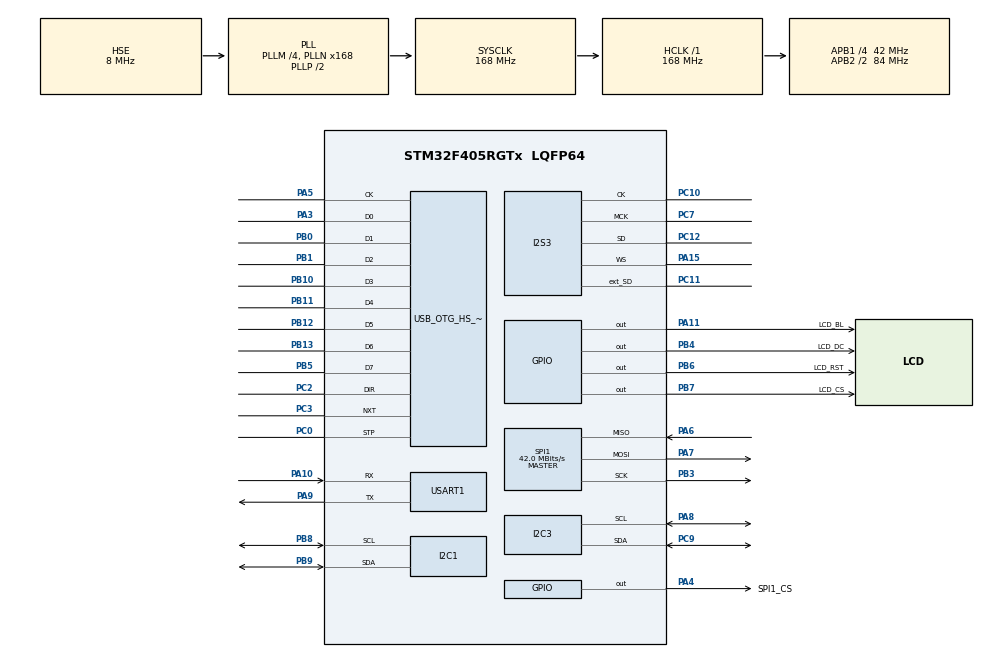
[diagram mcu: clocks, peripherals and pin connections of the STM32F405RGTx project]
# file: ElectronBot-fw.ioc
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Dma.I2C1_RX.5.Direction=DMA_PERIPH_TO_MEMORY
Dma.I2C1_RX.5.FIFOMode=DMA_FIFOMODE_DISABLE
Dma.I2C1_RX.5.Instance=DMA1_Stream5
Dma.I2C1_RX.5.MemDataAlignment=DMA_MDATAALIGN_BYTE
Dma.I2C1_RX.5.MemInc=DMA_MINC_ENABLE
Dma.I2C1_RX.5.Mode=DMA_NORMAL
Dma.I2C1_RX.5.PeriphDataAlignment=DMA_PDATAALIGN_BYTE
Dma.I2C1_RX.5.PeriphInc=DMA_PINC_DISABLE
Dma.I2C1_RX.5.Priority=DMA_PRIORITY_LOW
Dma.I2C1_TX.4.Direction=DMA_MEMORY_TO_PERIPH
Dma.I2C1_TX.4.FIFOMode=DMA_FIFOMODE_DISABLE
Dma.I2C1_TX.4.Instance=DMA1_Stream6
Dma.I2C1_TX.4.MemDataAlignment=DMA_MDATAALIGN_BYTE
Dma.I2C1_TX.4.MemInc=DMA_MINC_ENABLE
Dma.I2C1_TX.4.Mode=DMA_NORMAL
Dma.I2C1_TX.4.PeriphDataAlignment=DMA_PDATAALIGN_BYTE
Dma.I2C1_TX.4.PeriphInc=DMA_PINC_DISABLE
Dma.I2C1_TX.4.Priority=DMA_PRIORITY_LOW
Dma.I2C3_RX.7.Direction=DMA_PERIPH_TO_MEMORY
Dma.I2C3_RX.7.FIFOMode=DMA_FIFOMODE_DISABLE
Dma.I2C3_RX.7.Instance=DMA1_Stream2
Dma.I2C3_RX.7.MemDataAlignment=DMA_MDATAALIGN_BYTE
Dma.I2C3_RX.7.MemInc=DMA_MINC_ENABLE
Dma.I2C3_RX.7.Mode=DMA_NORMAL
Dma.I2C3_RX.7.PeriphDataAlignment=DMA_PDATAALIGN_BYTE
Dma.I2C3_RX.7.PeriphInc=DMA_PINC_DISABLE
Dma.I2C3_RX.7.Priority=DMA_PRIORITY_LOW
Dma.I2C3_TX.6.Direction=DMA_MEMORY_TO_PERIPH
Dma.I2C3_TX.6.FIFOMode=DMA_FIFOMODE_DISABLE
Dma.I2C3_TX.6.Instance=DMA1_Stream4
Dma.I2C3_TX.6.MemDataAlignment=DMA_MDATAALIGN_BYTE
Dma.I2C3_TX.6.MemInc=DMA_MINC_ENABLE
Dma.I2C3_TX.6.Mode=DMA_NORMAL
Dma.I2C3_TX.6.PeriphDataAlignment=DMA_PDATAALIGN_BYTE
Dma.I2C3_TX.6.PeriphInc=DMA_PINC_DISABLE
Dma.I2C3_TX.6.Priority=DMA_PRIORITY_LOW
Dma.I2S3_EXT_RX.3.Direction=DMA_PERIPH_TO_MEMORY
Dma.I2S3_EXT_RX.3.FIFOMode=DMA_FIFOMODE_DISABLE
Dma.I2S3_EXT_RX.3.Instance=DMA1_Stream0
Dma.I2S3_EXT_RX.3.MemDataAlignment=DMA_MDATAALIGN_HALFWORD
Dma.I2S3_EXT_RX.3.MemInc=DMA_MINC_ENABLE
Dma.I2S3_EXT_RX.3.Mode=DMA_NORMAL
Dma.I2S3_EXT_RX.3.PeriphDataAlignment=DMA_PDATAALIGN_HALFWORD
Dma.I2S3_EXT_RX.3.PeriphInc=DMA_PINC_DISABLE
Dma.I2S3_EXT_RX.3.Priority=DMA_PRIORITY_LOW
Dma.Request0=USART1_RX
Dma.Request1=USART1_TX
Dma.Request2=SPI3_TX
Dma.Request3=I2S3_EXT_RX
Dma.Request4=I2C1_TX
Dma.Request5=I2C1_RX
Dma.Request6=I2C3_TX
Dma.Request7=I2C3_RX
Dma.Request8=SPI1_RX
Dma.Request9=SPI1_TX
Dma.SPI1_RX.8.Direction=DMA_PERIPH_TO_MEMORY
Dma.SPI1_RX.8.FIFOMode=DMA_FIFOMODE_DISABLE
Dma.SPI1_RX.8.Instance=DMA2_Stream0
Dma.SPI1_RX.8.MemDataAlignment=DMA_MDATAALIGN_BYTE
Dma.SPI1_RX.8.MemInc=DMA_MINC_ENABLE
Dma.SPI1_RX.8.Mode=DMA_NORMAL
Dma.SPI1_RX.8.PeriphDataAlignment=DMA_PDATAALIGN_BYTE
Dma.SPI1_RX.8.PeriphInc=DMA_PINC_DISABLE
Dma.SPI1_RX.8.Priority=DMA_PRIORITY_LOW
Dma.SPI1_TX.9.Direction=DMA_MEMORY_TO_PERIPH
Dma.SPI1_TX.9.FIFOMode=DMA_FIFOMODE_DISABLE
Dma.SPI1_TX.9.Instance=DMA2_Stream3
Dma.SPI1_TX.9.MemDataAlignment=DMA_MDATAALIGN_BYTE
Dma.SPI1_TX.9.MemInc=DMA_MINC_ENABLE
Dma.SPI1_TX.9.Mode=DMA_NORMAL
Dma.SPI1_TX.9.PeriphDataAlignment=DMA_PDATAALIGN_BYTE
Dma.SPI1_TX.9.PeriphInc=DMA_PINC_DISABLE
Dma.SPI1_TX.9.Priority=DMA_PRIORITY_LOW
Dma.SPI3_TX.2.Direction=DMA_MEMORY_TO_PERIPH
Dma.SPI3_TX.2.FIFOMode=DMA_FIFOMODE_DISABLE
Dma.SPI3_TX.2.Instance=DMA1_Stream7
Dma.SPI3_TX.2.MemDataAlignment=DMA_MDATAALIGN_HALFWORD
Dma.SPI3_TX.2.MemInc=DMA_MINC_ENABLE
Dma.SPI3_TX.2.Mode=DMA_NORMAL
Dma.SPI3_TX.2.PeriphDataAlignment=DMA_PDATAALIGN_HALFWORD
Dma.SPI3_TX.2.PeriphInc=DMA_PINC_DISABLE
Dma.SPI3_TX.2.Priority=DMA_PRIORITY_LOW
Dma.USART1_RX.0.Direction=DMA_PERIPH_TO_MEMORY
Dma.USART1_RX.0.FIFOMode=DMA_FIFOMODE_DISABLE
Dma.USART1_RX.0.Instance=DMA2_Stream2
Dma.USART1_RX.0.MemDataAlignment=DMA_MDATAALIGN_BYTE
Dma.USART1_RX.0.MemInc=DMA_MINC_ENABLE
Dma.USART1_RX.0.Mode=DMA_CIRCULAR
Dma.USART1_RX.0.PeriphDataAlignment=DMA_PDATAALIGN_BYTE
Dma.USART1_RX.0.PeriphInc=DMA_PINC_DISABLE
Dma.USART1_RX.0.Priority=DMA_PRIORITY_LOW
Dma.USART1_TX.1.Direction=DMA_MEMORY_TO_PERIPH
Dma.USART1_TX.1.FIFOMode=DMA_FIFOMODE_DISABLE
Dma.USART1_TX.1.Instance=DMA2_Stream7
Dma.USART1_TX.1.MemDataAlignment=DMA_MDATAALIGN_BYTE
Dma.USART1_TX.1.MemInc=DMA_MINC_ENABLE
Dma.USART1_TX.1.Mode=DMA_NORMAL
Dma.USART1_TX.1.PeriphDataAlignment=DMA_PDATAALIGN_BYTE
Dma.USART1_TX.1.PeriphInc=DMA_PINC_DISABLE
Dma.USART1_TX.1.Priority=DMA_PRIORITY_LOW
FREERTOS.Tasks01=defaultTask,24,128,StartDefaultTask,Default,NULL,Dynamic,NULL,NULL
FREERTOS.configENABLE_FPU=1
FREERTOS.configTOTAL_HEAP_SIZE=10000
I2C1.I2C_Mode=I2C_Standard
I2S3.AudioFreq=I2S_AUDIOFREQ_44K
I2S3.DataFormat=I2S_DATAFORMAT_16B_EXTENDED
I2S3.ErrorAudioFreq=0.26 %
I2S3.FullDuplexMode=I2S_FULLDUPLEXMODE_ENABLE
I2S3.Instance=SPI$Index
I2S3.RealAudioFreq=44.117 KHz
I2S3.VirtualMode=I2S_MODE_MASTER
Mcu.Family=STM32F4
Mcu.Name=STM32F405RGTx
Mcu.Package=LQFP64
NVIC.DMA1_Stream0_IRQn=true\:5\:0\:false\:false\:true\:true\:false\:true
NVIC.DMA1_Stream2_IRQn=true\:5\:0\:false\:false\:true\:true\:false\:true
NVIC.DMA1_Stream4_IRQn=true\:5\:0\:false\:false\:true\:true\:false\:true
NVIC.DMA1_Stream5_IRQn=true\:5\:0\:false\:false\:true\:true\:false\:true
NVIC.DMA1_Stream6_IRQn=true\:5\:0\:false\:false\:true\:true\:false\:true
NVIC.DMA1_Stream7_IRQn=true\:5\:0\:false\:false\:true\:true\:false\:true
NVIC.DMA2_Stream0_IRQn=true\:5\:0\:false\:false\:true\:true\:false\:true
NVIC.DMA2_Stream2_IRQn=true\:5\:0\:false\:false\:true\:true\:false\:true
NVIC.DMA2_Stream3_IRQn=true\:5\:0\:false\:false\:true\:true\:false\:true
NVIC.DMA2_Stream7_IRQn=true\:5\:0\:false\:false\:true\:true\:false\:true
NVIC.I2C1_ER_IRQn=true\:5\:0\:false\:false\:true\:true\:true\:true
NVIC.I2C1_EV_IRQn=true\:5\:0\:false\:false\:true\:true\:true\:true
NVIC.I2C3_ER_IRQn=true\:5\:0\:false\:false\:true\:true\:true\:true
NVIC.I2C3_EV_IRQn=true\:5\:0\:false\:false\:true\:true\:true\:true
NVIC.OTG_HS_EP1_IN_IRQn=true\:5\:0\:false\:false\:true\:true\:true\:true
NVIC.OTG_HS_EP1_OUT_IRQn=true\:5\:0\:false\:false\:true\:true\:true\:true
NVIC.OTG_HS_IRQn=true\:5\:0\:false\:false\:true\:true\:false\:true
NVIC.PriorityGroup=NVIC_PRIORITYGROUP_4
NVIC.SPI1_IRQn=true\:5\:0\:false\:false\:true\:true\:true\:true
NVIC.SPI3_IRQn=true\:5\:0\:false\:false\:true\:true\:true\:true
NVIC.TIM4_IRQn=true\:5\:0\:false\:false\:true\:true\:true\:true
NVIC.TIM8_TRG_COM_TIM14_IRQn=true\:0\:0\:false\:false\:true\:false\:false\:true
NVIC.TimeBase=TIM8_TRG_COM_TIM14_IRQn
NVIC.TimeBaseIP=TIM14
NVIC.USART1_IRQn=true\:5\:0\:false\:false\:true\:true\:true\:true
PA10.Mode=Asynchronous
PA10.Signal=USART1_RX
PA11.GPIO_Label=LCD_BL
PA11.Signal=GPIO_Output
PA13.Mode=Serial_Wire
PA13.Signal=SYS_JTMS-SWDIO
PA14.Mode=Serial_Wire
PA14.Signal=SYS_JTCK-SWCLK
PA15.Mode=Full_Duplex_Master
PA15.Signal=I2S3_WS
PA3.Mode=Device_HS
PA3.Signal=USB_OTG_HS_ULPI_D0
PA4.GPIO_Label=SPI1_CS
PA4.GPIO_Speed=GPIO_SPEED_FREQ_VERY_HIGH
PA4.Signal=GPIO_Output
PA5.Mode=Device_HS
PA5.Signal=USB_OTG_HS_ULPI_CK
PA6.Mode=Full_Duplex_Master
PA6.Signal=SPI1_MISO
PA7.Mode=Full_Duplex_Master
PA7.Signal=SPI1_MOSI
PA8.Mode=I2C
PA8.Signal=I2C3_SCL
PA9.Mode=Asynchronous
PA9.Signal=USART1_TX
PB0.Mode=Device_HS
PB0.Signal=USB_OTG_HS_ULPI_D1
PB1.Mode=Device_HS
PB1.Signal=USB_OTG_HS_ULPI_D2
PB10.Mode=Device_HS
PB10.Signal=USB_OTG_HS_ULPI_D3
PB11.Mode=Device_HS
PB11.Signal=USB_OTG_HS_ULPI_D4
PB12.Mode=Device_HS
PB12.Signal=USB_OTG_HS_ULPI_D5
PB13.Mode=Device_HS
PB13.Signal=USB_OTG_HS_ULPI_D6
PB3.Mode=Full_Duplex_Master
PB3.Signal=SPI1_SCK
PB4.GPIO_Label=LCD_DC
PB4.GPIO_Speed=GPIO_SPEED_FREQ_VERY_HIGH
PB4.Signal=GPIO_Output
PB5.Mode=Device_HS
PB5.Signal=USB_OTG_HS_ULPI_D7
PB6.GPIO_Label=LCD_RST
PB6.GPIO_Speed=GPIO_SPEED_FREQ_VERY_HIGH
PB6.Signal=GPIO_Output
PB7.GPIO_Label=LCD_CS
PB7.GPIO_Speed=GPIO_SPEED_FREQ_VERY_HIGH
PB7.Signal=GPIO_Output
PB8.Mode=I2C
PB8.Signal=I2C1_SCL
PB9.Mode=I2C
PB9.Signal=I2C1_SDA
PC0.Mode=Device_HS
PC0.Signal=USB_OTG_HS_ULPI_STP
PC10.Mode=Full_Duplex_Master
PC10.Signal=I2S3_CK
PC11.Mode=Full_Duplex_Master
PC11.Signal=I2S3_ext_SD
PC12.Mode=Full_Duplex_Master
PC12.Signal=I2S3_SD
PC2.Mode=Device_HS
PC2.Signal=USB_OTG_HS_ULPI_DIR
PC3.Mode=Device_HS
PC3.Signal=USB_OTG_HS_ULPI_NXT
PC7.Mode=Master_Clock_Activated
PC7.Signal=I2S3_MCK
PC9.Mode=I2C
PC9.Signal=I2C3_SDA
PH0-OSC_IN.Mode=HSE-External-Oscillator
PH0-OSC_IN.Signal=RCC_OSC_IN
PH1-OSC_OUT.Mode=HSE-External-Oscillator
PH1-OSC_OUT.Signal=RCC_OSC_OUT
ProjectManager.HeapSize=0x800
ProjectManager.StackSize=0x800
ProjectManager.TargetToolchain=SW4STM32
RCC.48MHZClocksFreq_Value=48000000
RCC.AHBFreq_Value=168000000
RCC.APB1CLKDivider=RCC_HCLK_DIV4
RCC.APB1Freq_Value=42000000
RCC.APB1TimFreq_Value=84000000
RCC.APB2CLKDivider=RCC_HCLK_DIV2
RCC.APB2Freq_Value=84000000
RCC.APB2TimFreq_Value=168000000
RCC.CortexFreq_Value=168000000
RCC.HCLKFreq_Value=168000000
RCC.HSE_VALUE=8000000
RCC.HSI_VALUE=16000000
RCC.LSE_VALUE=32768
RCC.PLLM=4
RCC.PLLN=168
RCC.PLLQ=7
RCC.PLLSourceVirtual=RCC_PLLSOURCE_HSE
RCC.SYSCLKFreq_VALUE=168000000
RCC.SYSCLKSource=RCC_SYSCLKSOURCE_PLLCLK
RCC.VCOOutputFreq_Value=336000000
SPI1.CalculateBaudRate=42.0 MBits/s
SPI1.Direction=SPI_DIRECTION_2LINES
SPI1.Mode=SPI_MODE_MASTER
SPI1.VirtualType=VM_MASTER
TIM4.Period=100
TIM4.Prescaler=186 - 1
TIM4.TIM_MasterOutputTrigger=TIM_TRGO_UPDATE
TIM5.Prescaler=168 - 1
USART1.VirtualMode=VM_ASYNC
USB_DEVICE.APP_RX_DATA_SIZE-CDC_HS=4
USB_DEVICE.APP_TX_DATA_SIZE-CDC_HS=4
USB_DEVICE.CLASS_NAME_HS=CDC
USB_DEVICE.PID_CDC_HS=32803
USB_DEVICE.VID-CDC_HS=4097
USB_DEVICE.VirtualMode-CDC_HS=Cdc
USB_DEVICE.VirtualModeHS=Cdc_HS
USB_OTG_HS.VirtualMode-Device_HS=Device_HS
USB_OTG_HS.dma_enable-Device_HS=ENABLE
VP_FREERTOS_VS_CMSIS_V2.Mode=CMSIS_V2
VP_SYS_VS_tim14.Mode=TIM14
VP_TIM4_VS_ClockSourceINT.Mode=Internal
VP_TIM5_VS_ClockSourceINT.Mode=Internal
VP_USB_DEVICE_VS_USB_DEVICE_CDC_HS.Mode=CDC_HS
board=custom

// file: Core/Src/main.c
/* USER CODE BEGIN Header */
/**
  ******************************************************************************
  * @file           : main.c
  * @brief          : Main program body
  ******************************************************************************
  * @attention
  *
  * <h2><center>&copy; Copyright (c) 2021 STMicroelectronics.
  * All rights reserved.</center></h2>
  *
  * This software component is licensed by ST under BSD 3-Clause license,
  * the "License"; You may not use this file except in compliance with the
  * License. You may obtain a copy of the License at:
  *                        opensource.org/licenses/BSD-3-Clause
  *
  ******************************************************************************
  */
/* USER CODE END Header */
#include "main.h"
#include "cmsis_os.h"
#include "dma.h"
#include "i2c.h"
#include "i2s.h"
#include "spi.h"
#include "tim.h"
#include "usart.h"
#include "usb_device.h"
#include "gpio.h"

/* USER CODE BEGIN PV */

// uint8_t completed = 1;

/* USER CODE END PV */

void SystemClock_Config(void);
void MX_FREERTOS_Init(void);

int main(void)
{

  /* MCU Configuration--------------------------------------------------------*/

  /* Reset of all peripherals, Initializes the Flash interface and the Systick. */
  HAL_Init();

  /* USER CODE BEGIN Init */
    HAL_RCC_DeInit();
  /* USER CODE END Init */

  /* Configure the system clock */
  SystemClock_Config();

  /* Initialize all configured peripherals */
  MX_GPIO_Init();
  MX_DMA_Init();
  MX_USART1_UART_Init();
  MX_I2C1_Init();
  MX_I2C3_Init();
  MX_I2S3_Init();
  MX_TIM4_Init();
  MX_TIM5_Init();
  MX_SPI1_Init();

  /* Init scheduler */
  osKernelInitialize();  /* Call init function for freertos objects (in freertos.c) */
  MX_FREERTOS_Init();
  /* Start scheduler */
  osKernelStart();

  /* We should never get here as control is now taken by the scheduler */
  /* Infinite loop */
    while (1)
    {

    }
}

void SystemClock_Config(void)
{
  RCC_OscInitTypeDef RCC_OscInitStruct = {0};
  RCC_ClkInitTypeDef RCC_ClkInitStruct = {0};
  RCC_PeriphCLKInitTypeDef PeriphClkInitStruct = {0};

  /** Configure the main internal regulator output voltage
  */
  __HAL_RCC_PWR_CLK_ENABLE();
  __HAL_PWR_VOLTAGESCALING_CONFIG(PWR_REGULATOR_VOLTAGE_SCALE1);
  /** Initializes the RCC Oscillators according to the specified parameters
  * in the RCC_OscInitTypeDef structure.
  */
  RCC_OscInitStruct.OscillatorType = RCC_OSCILLATORTYPE_HSE;
  RCC_OscInitStruct.HSEState = RCC_HSE_ON;
  RCC_OscInitStruct.PLL.PLLState = RCC_PLL_ON;
  RCC_OscInitStruct.PLL.PLLSource = RCC_PLLSOURCE_HSE;
  RCC_OscInitStruct.PLL.PLLM = 4;
  RCC_OscInitStruct.PLL.PLLN = 168;
  RCC_OscInitStruct.PLL.PLLP = RCC_PLLP_DIV2;
  RCC_OscInitStruct.PLL.PLLQ = 7;
  if (HAL_RCC_OscConfig(&RCC_OscInitStruct) != HAL_OK)
  {
    Error_Handler();
  }
  /** Initializes the CPU, AHB and APB buses clocks
  */
  RCC_ClkInitStruct.ClockType = RCC_CLOCKTYPE_HCLK|RCC_CLOCKTYPE_SYSCLK
                              |RCC_CLOCKTYPE_PCLK1|RCC_CLOCKTYPE_PCLK2;
  RCC_ClkInitStruct.SYSCLKSource = RCC_SYSCLKSOURCE_PLLCLK;
  RCC_ClkInitStruct.AHBCLKDivider = RCC_SYSCLK_DIV1;
  RCC_ClkInitStruct.APB1CLKDivider = RCC_HCLK_DIV4;
  RCC_ClkInitStruct.APB2CLKDivider = RCC_HCLK_DIV2;

  if (HAL_RCC_ClockConfig(&RCC_ClkInitStruct, FLASH_LATENCY_5) != HAL_OK)
  {
    Error_Handler();
  }
  PeriphClkInitStruct.PeriphClockSelection = RCC_PERIPHCLK_I2S;
  PeriphClkInitStruct.PLLI2S.PLLI2SN = 192;
  PeriphClkInitStruct.PLLI2S.PLLI2SR = 2;
  if (HAL_RCCEx_PeriphCLKConfig(&PeriphClkInitStruct) != HAL_OK)
  {
    Error_Handler();
  }
}

 /**
  * @brief  Period elapsed callback in non blocking mode
  * @note   This function is called  when TIM14 interrupt took place, inside
  * HAL_TIM_IRQHandler(). It makes a direct call to HAL_IncTick() to increment
  * a global variable "uwTick" used as application time base.
  * @param  htim : TIM handle
  * @retval None
  */
void HAL_TIM_PeriodElapsedCallback(TIM_HandleTypeDef *htim)
{
  if (htim->Instance == TIM14) {
    HAL_IncTick();
  }
}

void Error_Handler(void)
{
    __disable_irq();
    while (1)
    {
    }
}

/************************ (C) COPYRIGHT STMicroelectronics *****END OF FILE****/

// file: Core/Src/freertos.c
/* USER CODE BEGIN Header */
/**
  ******************************************************************************
  * File Name          : freertos.c
  * Description        : Code for freertos applications
  ******************************************************************************
  * @attention
  *
  * <h2><center>&copy; Copyright (c) 2022 STMicroelectronics.
  * All rights reserved.</center></h2>
  *
  * This software component is licensed by ST under Ultimate Liberty license
  * SLA0044, the "License"; You may not use this file except in compliance with
  * the License. You may obtain a copy of the License at:
  *                             www.st.com/SLA0044
  *
  ******************************************************************************
  */
/* USER CODE END Header */

#include "FreeRTOS.h"
#include "task.h"
#include "main.h"
#include "cmsis_os.h"

/* USER CODE BEGIN Includes */
#include "common_inc.h"
/* USER CODE END Includes */

/* USER CODE BEGIN Variables */
//__attribute__((section(".ccmram"))) uint8_t ucHeap[configTOTAL_HEAP_SIZE];

/* USER CODE END Variables */
/* Definitions for defaultTask */
osThreadId_t defaultTaskHandle;
const osThreadAttr_t defaultTask_attributes = {
  .name = "defaultTask",
  .stack_size = 128 * 4,
  .priority = (osPriority_t) osPriorityNormal,
};

/* USER CODE BEGIN FunctionPrototypes */
osThreadId_t audioTaskHandle;
const osThreadAttr_t audioTask_attributes = {
        .name = "audioTask",
        .stack_size = 128 * 8,
        .priority = (osPriority_t) osPriorityAboveNormal,
};

void StartAudioTask(void *argument);

/* USER CODE END FunctionPrototypes */

void StartDefaultTask(void *argument);

extern void MX_USB_DEVICE_Init(void);
void MX_FREERTOS_Init(void); /* (MISRA C 2004 rule 8.1) */

void MX_FREERTOS_Init(void) {

  /* Create the thread(s) */
  /* creation of defaultTask */
  defaultTaskHandle = osThreadNew(StartDefaultTask, NULL, &defaultTask_attributes);

}

void StartDefaultTask(void *argument)
{
  /* init code for USB_DEVICE */
  MX_USB_DEVICE_Init();
  /* USER CODE BEGIN StartDefaultTask */

    // Invoke cpp-version main().
//    Main();
    audioTaskHandle  = osThreadNew(StartAudioTask, NULL,  &audioTask_attributes);
    vTaskDelete(defaultTaskHandle);
  /* USER CODE END StartDefaultTask */
}

/* USER CODE BEGIN Application */
void StartAudioTask(void *argument)
{
    TaskAudioEntry();
}
/* USER CODE END Application */

/************************ (C) COPYRIGHT STMicroelectronics *****END OF FILE****/
